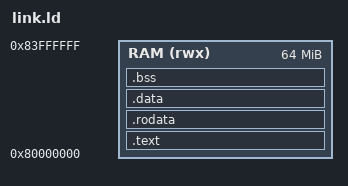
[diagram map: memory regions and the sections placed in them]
/* Bare-metal layout for rv-doom: everything in one RAM region at 0x80000000. */
OUTPUT_ARCH("riscv")
ENTRY(_start)
MEMORY { RAM (rwx) : ORIGIN = 0x80000000, LENGTH = 64M }
SECTIONS
{
  .text   : { *(.text.init) *(.text .text.*) } > RAM
  .rodata : { *(.rodata .rodata.* .srodata .srodata.*) } > RAM
  .data   : { *(.data .data.* .sdata .sdata.*) } > RAM
  .bss (NOLOAD) : ALIGN(4) {
    _bss_start = .;
    *(.bss .bss.* .sbss .sbss.* COMMON)
    . = ALIGN(4);
    _bss_end = .;
  } > RAM
  _stack_top = ORIGIN(RAM) + LENGTH(RAM);
}
